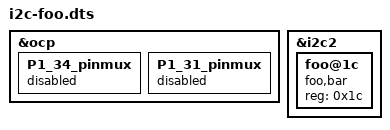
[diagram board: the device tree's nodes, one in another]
/dts-v1/;
/plugin/;
/ {
	fragment@0 {
		target = <&ocp>;
		__overlay__ {
			P1_34_pinmux {
				status = "disabled";
			};
			P1_31_pinmux {
				status = "disabled";
			};
		};
	};

	fragment@1 {
		target = <&i2c2>;
		__overlay__ {
			#address-cells = <1>;
			#size-cells = <0>;
			foo@1c {
				status = "okay";
				compatible = "foo,bar";
				reg = <0x1c>;
			};
		};
	};
};
